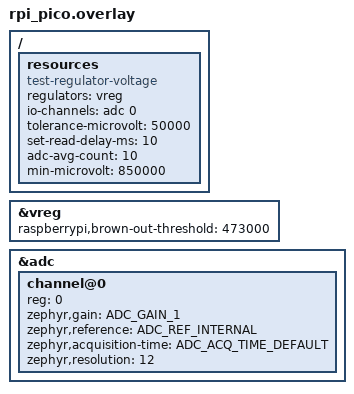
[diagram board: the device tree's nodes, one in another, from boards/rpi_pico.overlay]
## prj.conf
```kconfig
# Copyright (c) 2022 Nordic Semiconductor ASA
# SPDX-License-Identifier: Apache-2.0

CONFIG_ZTEST=y
CONFIG_ZTEST_NEW_API=y
CONFIG_ADC=y
CONFIG_REGULATOR=y
```

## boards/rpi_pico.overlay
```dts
/*
 * Copyright (c) 2023 TOKITA Hiroshi <tokita.hiroshi@fujitsu.com>
 * SPDX-License-Identifier: Apache-2.0
 */

/ {
        /* NOTE: It is necessary to connect VREG_OUT to the ADC to perform the test.
	 * But the rpi_pico board and most boards that use the rp2040, VREG_OUT and
	 * DVDD are directly connected, and no available exposed trace on the board.
	 *
	 * In the rpi_pico board, a short, thick, diagonal wiring pattern near the 3x3
	 * thermal via connect to VREG_OUT. (Around between C and E of CE mark of silk print.)
	 * Scraping the resist on there and soldering wire to make it able to measure by ADC.
	 */
	resources: resources {
		compatible = "test-regulator-voltage";
		regulators = <&vreg>;
		io-channels = <&adc 0>;
		tolerance-microvolt = <50000>;
		set-read-delay-ms = <10>;
		adc-avg-count = <10>;
		min-microvolt = <850000>;
	};
};

&vreg {
	raspberrypi,brown-out-threshold = <473000>;
};

&adc {
	#address-cells = <1>;
	#size-cells = <0>;

	channel@0 {
		reg = <0>;
		zephyr,gain = "ADC_GAIN_1";
		zephyr,reference = "ADC_REF_INTERNAL";
		zephyr,acquisition-time = <ADC_ACQ_TIME_DEFAULT>;
		zephyr,resolution = <12>;
	};
};
```

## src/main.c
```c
/*
 * Copyright (c) 2022 Nordic Semiconductor ASA
 * SPDX-License-Identifier: Apache-2.0
 */

#include <zephyr/device.h>
#include <zephyr/devicetree.h>
#include <zephyr/drivers/adc.h>
#include <zephyr/drivers/regulator.h>
#include <zephyr/sys/util.h>
#include <zephyr/ztest.h>

#define REG_INIT(node_id, prop, idx) \
	DEVICE_DT_GET(DT_PHANDLE_BY_IDX(node_id, prop, idx)),

#define ADC_INIT(node_id, prop, idx) \
	ADC_DT_SPEC_GET_BY_IDX(node_id, idx),

static const struct device *regs[] = {
	DT_FOREACH_PROP_ELEM(DT_NODELABEL(resources), regulators, REG_INIT)
};

static const struct adc_dt_spec adc_chs[] = {
	DT_FOREACH_PROP_ELEM(DT_NODELABEL(resources), io_channels, ADC_INIT)
};

static const int32_t tols[] =
	DT_PROP(DT_NODELABEL(resources), tolerance_microvolt);

static const unsigned int adc_avg_count = DT_PROP(DT_NODELABEL(resources),
						  adc_avg_count);
static const int32_t set_read_delay_ms = DT_PROP(DT_NODELABEL(resources),
						 set_read_delay_ms);

static const int32_t min_microvolt = DT_PROP(DT_NODELABEL(resources), min_microvolt);
static const int32_t max_microvolt = DT_PROP(DT_NODELABEL(resources), max_microvolt);

ZTEST(regulator_voltage, test_output_voltage)
{
	int16_t buf;
	struct adc_sequence sequence = {
		.buffer = &buf,
		.buffer_size = sizeof(buf),
	};

	for (size_t i = 0U; i < ARRAY_SIZE(regs); i++) {
		int ret;
		unsigned int volt_cnt;
		int32_t volt_uv;

		ret = adc_sequence_init_dt(&adc_chs[i], &sequence);
		zassert_equal(ret, 0);

		volt_cnt = regulator_count_voltages(regs[i]);
		zassume_not_equal(volt_cnt, 0U);

		TC_PRINT("Testing %s, %u voltage/s (tolerance: %d uV)\n",
			 regs[i]->name, volt_cnt, tols[i]);

		ret = regulator_enable(regs[i]);
		zassert_equal(ret, 0);

		for (unsigned int j = 0U; j < volt_cnt; j++) {
			int32_t val_mv = 0;

			(void)regulator_list_voltage(regs[i], j, &volt_uv);
			/* Check if voltage is outside user constraints */
			if (!regulator_is_supported_voltage(regs[i],
				volt_uv, volt_uv)) {
				continue;
			}

			if ((volt_uv < min_microvolt) || (volt_uv > max_microvolt)) {
				TC_PRINT("Skip: %d uV\n", volt_uv);
				continue;
			}

			ret = regulator_set_voltage(regs[i], volt_uv, volt_uv);
			zassert_equal(ret, 0);

			if (set_read_delay_ms > 0) {
				k_msleep(set_read_delay_ms);
			}

			for (unsigned int k = 0U; k < adc_avg_count; k++) {
				ret = adc_read(adc_chs[i].dev, &sequence);
				zassert_equal(ret, 0);

				val_mv += buf;
			}

			val_mv /= (int32_t)adc_avg_count;

			ret = adc_raw_to_millivolts_dt(&adc_chs[i], &val_mv);
			zassert_equal(ret, 0);

			TC_PRINT("Set: %d, read: %d uV\n", volt_uv,
				 val_mv * 1000);

			zassert_between_inclusive(val_mv * 1000,
						  volt_uv - tols[i],
						  volt_uv + tols[i]);
		}

		ret = regulator_disable(regs[i]);
		zassert_equal(ret, 0);
	}
}

void *setup(void)
{
	zassert_equal(ARRAY_SIZE(regs), ARRAY_SIZE(adc_chs));
	zassert_equal(ARRAY_SIZE(regs), ARRAY_SIZE(tols));

	for (size_t i = 0U; i < ARRAY_SIZE(regs); i++) {
		zassert_true(device_is_ready(regs[i]));
		zassert_true(adc_is_ready_dt(&adc_chs[i]));
		zassert_equal(adc_channel_setup_dt(&adc_chs[i]), 0);
	}

	return NULL;
}

ZTEST_SUITE(regulator_voltage, NULL, setup, NULL, NULL, NULL);
```
